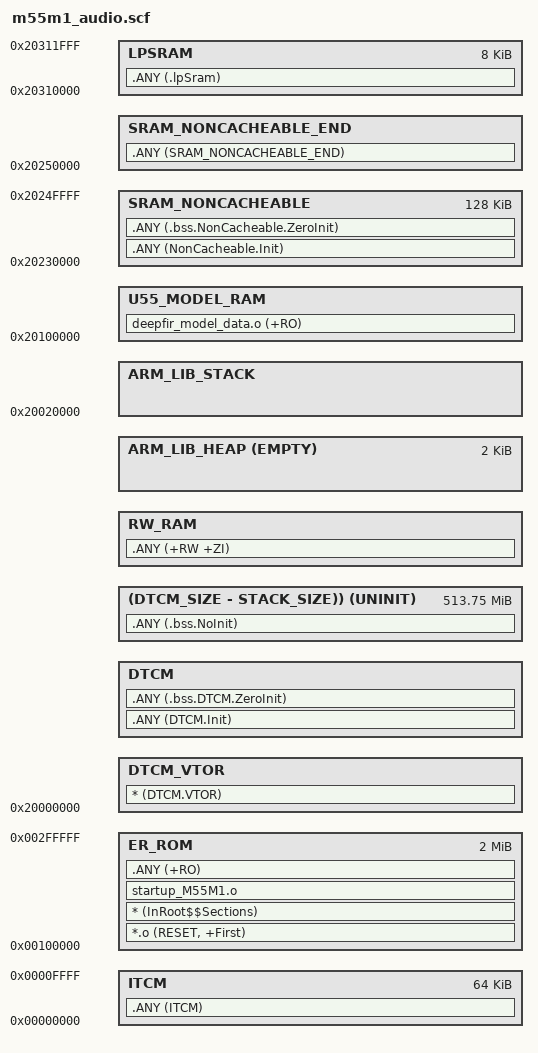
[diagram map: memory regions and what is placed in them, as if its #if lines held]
#! armclang -E --target=arm-arm-none-eabi -mcpu=cortex-m55 -xc
; Generic M55M1 audio scatter file for the model-free firmware baseline.

#define FLASH_START 0x00100000
#define FLASH_SIZE 0x00200000
#define SRAM_START 0x20100000
#define SRAM_SIZE 0x00150000
#define SRAM_CACHEABLE_SIZE 0x00130000
#define SRAM_NONCACHEABLE_START (SRAM_START + SRAM_CACHEABLE_SIZE)
#define SRAM_NONCACHEABLE_SIZE (SRAM_SIZE - SRAM_CACHEABLE_SIZE)
#define LPSRAM_START 0x20310000
#define LPSRAM_SIZE 0x00002000
#define ITCM_START 0x00000000
#define ITCM_SIZE 0x00010000
#define DTCM_START 0x20000000
#define DTCM_SIZE 0x00020000

#ifndef STACK_SIZE
#define STACK_SIZE 0x00000800
#endif
#ifndef HEAP_SIZE
#define HEAP_SIZE 0x00000800
#endif

#if defined(M55M1_MODEL_IN_SRAM)
#define MODEL_IMAGE_SRAM_SIZE 0x000C0000
#define __RW_BASE (SRAM_START + MODEL_IMAGE_SRAM_SIZE)
#define __RW_SIZE (SRAM_CACHEABLE_SIZE - MODEL_IMAGE_SRAM_SIZE - HEAP_SIZE)
#else
#define __RW_BASE SRAM_START
#define __RW_SIZE (SRAM_CACHEABLE_SIZE - HEAP_SIZE)
#endif

#define __RO_BASE FLASH_START
#define __RO_SIZE FLASH_SIZE
#define __STACK_TOP (DTCM_START + DTCM_SIZE)
#define __HEAP_BASE (AlignExpr(+0, 8))

LR_ROM __RO_BASE __RO_SIZE {
    ER_ROM __RO_BASE __RO_SIZE {
        *.o (RESET, +First)
        * (InRoot$$Sections)
        startup_M55M1.o
        .ANY (+RO)
    }

#if defined(M55M1_MODEL_IN_SRAM)
    U55_MODEL_RAM SRAM_START {
        deepfir_model_data.o (+RO)
    }
#endif

    ITCM ITCM_START ITCM_SIZE {
        .ANY (ITCM)
    }

    DTCM_VTOR DTCM_START {
        * (DTCM.VTOR)
    }

    DTCM AlignExpr(+0, 8) {
        .ANY (DTCM.Init)
        .ANY (.bss.DTCM.ZeroInit)
    }

    ScatterAssert((ImageLength(DTCM_VTOR) + ImageLength(DTCM)) <
                  (DTCM_SIZE - STACK_SIZE))

    RW_NOINIT __RW_BASE UNINIT __RW_SIZE {
        .ANY (.bss.NoInit)
    }

    RW_RAM AlignExpr(+0, 8) {
        .ANY (+RW +ZI)
    }

    ScatterAssert((ImageLength(RW_NOINIT) + ImageLength(RW_RAM)) < __RW_SIZE)

#if defined(M55M1_MODEL_IN_SRAM)
    ScatterAssert(ImageLength(U55_MODEL_RAM) <= MODEL_IMAGE_SRAM_SIZE)
#endif
#if HEAP_SIZE > 0
    ARM_LIB_HEAP __HEAP_BASE EMPTY HEAP_SIZE {}
#endif

    SRAM_NONCACHEABLE SRAM_NONCACHEABLE_START SRAM_NONCACHEABLE_SIZE {
        .ANY (NonCacheable.Init)
        .ANY (.bss.NonCacheable.ZeroInit)
    }

    SRAM_NONCACHEABLE_END
        (SRAM_NONCACHEABLE_START + SRAM_NONCACHEABLE_SIZE) {
        .ANY (SRAM_NONCACHEABLE_END)
    }

    LPSRAM LPSRAM_START LPSRAM_SIZE {
        .ANY (.lpSram)
    }

    ARM_LIB_STACK __STACK_TOP EMPTY - STACK_SIZE {}
}
